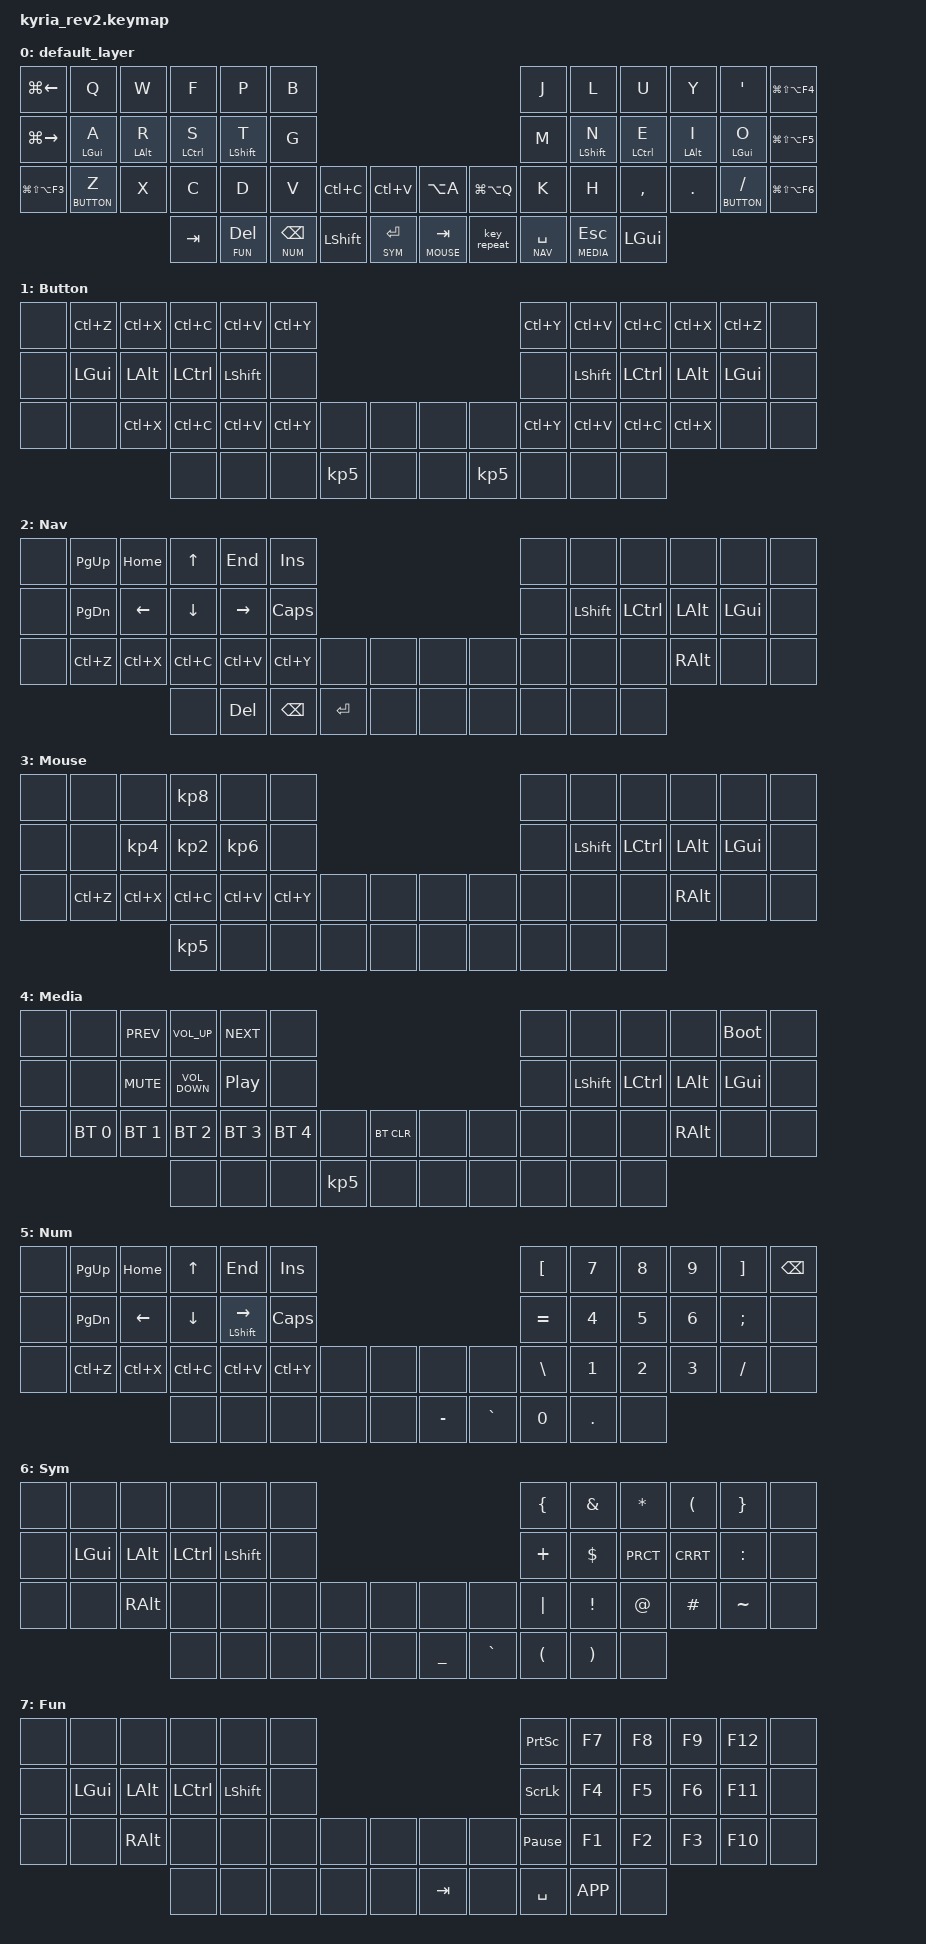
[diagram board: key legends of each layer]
/*
 * Copyright (c) 2020 The ZMK Contributors
 *
 * SPDX-License-Identifier: MIT
 */

#include <behaviors.dtsi>
#include <dt-bindings/zmk/bt.h>
#include <dt-bindings/zmk/keys.h>
// #include <dt-bindings/zmk/outputs.h>


// LAYER DEFINITIONS //
#define BASE   0
#define BUTTON 1
#define NAV    2
#define MOUSE  3
#define MEDIA  4
#define NUM    5
#define SYM    6
#define FUN    7

// CUSTOM KEY DEFINITIONS //
#define U_RDO &kp LC(Y) // WINDOWS redo
#define U_PST &kp LC(V) // WINDOWS paste
#define U_CPY &kp LC(C) // WINDOWS copy
#define U_CUT &kp LC(X) // WINDOWS cut
#define U_UND &kp LC(Z) // WINDOWS undo
#define U_SCRNSHT &kp LG(LS(S)) // WINDOWS screenshot
#define U_A_TAB &kp LA(TAB) // Alt + Tab
#define U_RUNNER &kp LA(SPACE) // Alt + Space (notes: on windows, it's slow)
#define U_M1 &kp LG(LS(LA(F1))) // To be used in conjuction with AutoHotKey
#define U_M2 &kp LG(LS(LA(F2)))
#define U_M3 &kp LG(LS(LA(F3)))
#define U_M4 &kp LG(LS(LA(F4)))
#define U_M5 &kp LG(LS(LA(F5)))
#define U_M6 &kp LG(LS(LA(F6)))
#define U_M7 &kp LG(LS(LA(F7)))
#define U_M8 &kp LG(LS(LA(F8)))

#define U_BTN1 &kp KP_N5
#define U_BTN2 &none
#define U_BTN3 &none
#define U_MS_D &kp KP_N2
#define U_MS_L &kp KP_N4
#define U_MS_R &kp KP_N6
#define U_MS_U &kp KP_N8
#define U_WH_D &none
#define U_WH_L &none
#define U_WH_R &none
#define U_WH_U &none

// HOME ROW MOD CUSTOMIZATIONS //
#define U_TAPPING_TERM 1000
#define U_TAPPING_TERM_FAST 150
#define U_TIMEOUT 50

// &left_encoder { resolution = <2>; };
// &right_encoder { resolution = <2>; };

// Shortcuts //


/ {

    macros {
/*
        my_macro: my_macro {
        compatible = "zmk,behavior-macro";
        label = "ZM_LR_BKT";
        #binding-cells = <0>;
        wait-ms = <30>;
        tap-ms = <40>;
        bindings = <&kp LBKT &kp RBKT &kp SPACE>;
        };
    
    win_right: win_right {
      label = "ZM_win_right";
      compatible = "zmk,behavior-macro";
      #binding-cells = <0>;
      wait-ms = <10>;
      bindings
        = <&macro_press &kp LGUI>
        , <&macro_tap &kp RIGHT>
        , <&macro_release &kp LGUI>
        ;
    };

    */
  };

/*
 * Layout Indices
 * 00 01 02 03 04 05               06 07 08 09 10 11
 * 12 13 14 15 16 17               18 19 20 21 22 23
 * 24 25 26 27 28 29 30 31   32 33 34 35 36 37 38 39
 *          40 41 42 43 44   45 46 47 48 49         
 */

    combos {
        compatible = "zmk,combos";
        combo_esc {
        timeout-ms = <50>;
        key-positions = <02 03>;
        bindings = <&kp ESC>;
        //layers = <BASE SYM NUM NAV>;
        };
        compatible = "zmk,combos";
        combo_screenshot {
        timeout-ms = <50>;
        key-positions = <30 31>;
        bindings = <U_SCRNSHT>;
        //layers = <BASE SYM NUM NAV>;
        };
        compatible = "zmk,combos";
        combo_leaveZoomMeeting {
        timeout-ms = <50>;
        key-positions = <32 33>;
        bindings = <&kp LA(Q)>;
        //layers = <BASE SYM NUM NAV>;
        };
        compatible = "zmk,combos";
        combo_alttab {
        timeout-ms = <50>;
        key-positions = <03 04>;
        bindings = <&kp LA(TAB)>;
        //layers = <BASE SYM NUM NAV>;
        };
        /*
        compatible = "zmk,combos";
        combo_sqrBracketsL {
        timeout-ms = <50>;
        key-positions = <07 08>;
        bindings = <&kp LBKT>;
        //layers = <BASE SYM NUM NAV>;
        };
        compatible = "zmk,combos";
        combo_sqrBracketsR {
        timeout-ms = <50>;
        key-positions = <08 09>;
        bindings = <&kp RBKT>;
        //layers = <BASE SYM NUM NAV>;
        };
        
        compatible = "zmk,combos";
        combo_LPAR {
        timeout-ms = <50>;
        key-positions = <19 20>;
        bindings = <&kp LPAR>;
        //layers = <BASE SYM NUM NAV>;
        };
        compatible = "zmk,combos";
        combo_RPAR {
        timeout-ms = <50>;
        key-positions = <20 21>;
        bindings = <&kp RPAR>;
        //layers = <BASE SYM NUM NAV>;
        };
        /*
        compatible = "zmk,combos";
        combo_leaveZoomMeeting {
        timeout-ms = <50>;
        key-positions = <07 08>;
        bindings = <&my_macro>;
        //layers = <BASE SYM NUM NAV>;
        };
        */
  };
    
    behaviors {
    hm: homerow_mods {
      compatible = "zmk,behavior-hold-tap";
      label = "HOMEROW_MODS";
      #binding-cells = <2>;
      tapping_term_ms = <U_TAPPING_TERM>;
      flavor = "tap-preferred";
      bindings = <&kp>, <&kp>;
    };
    // for faster tapping terms
    hmf: homerow_mods_fast {
      compatible = "zmk,behavior-hold-tap";
      label = "HOMEROW_MODS";
      #binding-cells = <2>;
      tapping_term_ms = <U_TAPPING_TERM_FAST>;
      flavor = "tap-preferred";
      bindings = <&kp>, <&kp>;
    };

    /*
    hm_l: homerow_mods_left {
        compatible = "zmk,behavior-hold-tap";
        label = "HOMEROW_MODS_LEFT";
        #binding-cells = <2>;
        bindings = <&kp>,  <&kp>;

        flavor = "balanced";
        tapping-term-ms = <HM_TAPPING_TERM>;
        quick-tap-ms = <175>;                // repeat on tap-into-hold
        global-quick-tap-ms = <150>;         // requires PR #1387
        hold-trigger-key-positions = <KEYS_R KEYS_T>;
        hold-trigger-on-release;             // requires PR #1423
    };

    hm_r: homerow_mods_right {
        compatible = "zmk,behavior-hold-tap";
        label = "HOMEROW_MODS_RIGHT";
        #binding-cells = <2>;
        bindings = <&kp>, <&kp>;

        flavor = "balanced";
        tapping-term-ms = <HM_TAPPING_TERM>;   
        quick_tap_ms = <175>;
        global-quick-tap-ms = <150>;         // requires PR #1387
        hold-trigger-key-positions = <KEYS_L KEYS_T>;
        hold-trigger-on-release;             // requires PR #1423
    };
    */




  };
};

/{

	keymap {
		compatible = "zmk,keymap";

		default_layer {
            
            //                                                  BASE LAYER (no longer up-to-date)
            // ╭──────────────────────────────────────────╮                             ╭──────────────────────────────────────────╮
            // │ ESC   Q         W      F       P       B │                             │ J  L       U       Y      '         BSPC │
            // │ CTRL  A         R      S       T|SHFT  G ╰───────────────╮ ╭───────────╯ M  N|SHFT  E       I      O         CNTX │
            // │ ALT   Z|BUTTON  X|ALT  C       D       V  NONE   NONE    │ │ NONE  NONE  K  H       ,       .|ALT  /|BUTTON  CTRL │
            // ╰───────────╮   SCRN  DEL|FUN  BSPC|NUM  TAB|TAB   RED|SYM │ │ TAB|MOUSE  NONE  SPC|NAV  ESC|MEDIA  WIN  ╭──────────╯
            //             ╰──────────────────────────────────────────────╯ ╰───────────────────────────────────────────╯            
            //

			bindings = <
                &kp LG(LEFT)     &kp Q             &kp W              &kp F              &kp P              &kp B                                                               &kp J               &kp L               &kp U               &kp Y               &kp SQT           U_M4
                &kp LG(RIGHT)    &hm LGUI A        &hm LALT R         &hm LCTRL S        &hmf LSHFT T       &kp G                                                               &kp M               &hmf LSHFT N        &hm LCTRL E         &hm LALT I          &hm LGUI O        U_M5
                U_M3             &lt BUTTON Z      &kp X              &kp C              &kp D              &kp V         U_CPY         U_PST        &kp LA(A)     &kp LG(LA(Q))&kp K               &kp H               &kp COMMA           &kp DOT             &lt BUTTON SLASH  U_M6
                                                                      &kp TAB            &lt FUN DEL        &lt NUM BSPC  &kp LSHIFT    &lt SYM RET  &lt MOUSE TAB &key_repeat  &lt NAV SPC         &lt MEDIA ESC       &kp LGUI
			>;
            sensor-bindings = <&inc_dec_kp C_VOL_UP C_VOL_DN>;
			//sensor-bindings = <&inc_dec_kp DOWN UP &inc_dec_kp PG_DN PG_UP>;
		};

        BUTTON_layer {                                       
              label = "Button"; //MIRYOKU_ALTERNATIVES_BUTTON                                      
            bindings = <                                       
                &none  U_UND             U_CUT              U_CPY              U_PST              U_RDO                                                            U_RDO               U_PST               U_CPY               U_CUT               U_UND             &none
                &none  &kp LGUI          &kp LALT           &kp LCTRL          &kp LSHFT          &none                                                            &none               &kp LSHFT           &kp LCTRL           &kp LALT            &kp LGUI          &none
                &none  &none             U_CUT              U_CPY              U_PST              U_RDO         &none          &none     &none      &none          U_RDO               U_PST               U_CPY               U_CUT               &none             &none
                                                            &none              U_BTN2             U_BTN3        U_BTN1         &none     &none      U_BTN1         U_BTN3              U_BTN2              &none
            >;        
        };  
        NAV_layer {  
            label = "Nav";  //MIRYOKU_ALTERNATIVES_NAV_INVERTEDT_FLIP
            bindings = <  
                &none  &kp PG_UP         &kp HOME           &kp UP             &kp END            &kp INS                                                          &none               &none               &none               &none               &none            &none
                &none  &kp PG_DN         &kp LEFT           &kp DOWN           &kp RIGHT          &kp CAPS                                                         &none               &kp LSHFT           &kp LCTRL           &kp LALT            &kp LGUI         &none
                &none  U_UND             U_CUT              U_CPY              U_PST              U_RDO         &none          &none     &none      &none          &none               &none               &none               &kp RALT            &none            &none
                                                            &none              &kp DEL            &kp BSPC      &kp RET        &none     &none      &none          &none               &none               &none   
            >;      
        };      
        MOUSE_layer {      
            label = "Mouse"; //MIRYOKU_ALTERNATIVES_MOUSE_INVERTEDT_FLIP     
            bindings = <     
                &none  U_WH_U            U_WH_L             U_MS_U             U_WH_R             &none                                                            &none               &none               &none               &none               &none            &none   
                &none  U_WH_D            U_MS_L             U_MS_D             U_MS_R             &none                                                            &none               &kp LSHFT           &kp LCTRL           &kp LALT            &kp LGUI         &none   
                &none  U_UND             U_CUT              U_CPY              U_PST              U_RDO         &none          &none     &none      &none          &none               &none               &none               &kp RALT            &none            &none   
                                                            U_BTN1             U_BTN2             U_BTN3        &none          &none     &none      &none          &none               &none               &none
            >;      
        };      
        MEDIA_layer {      
            label = "Media"; //MIRYOKU_ALTERNATIVES_MEDIA_INVERTEDT_FLIP
            bindings = <       
                &none  &none             &kp C_PREV         &kp C_VOL_UP       &kp C_NEXT         &none                                                            &none               &none               &none               &none               &bootloader      &none   
                &none  &none             &kp C_MUTE         &kp C_VOLUME_DOWN  &kp C_PLAY_PAUSE   &none                                                            &none               &kp LSHFT           &kp LCTRL           &kp LALT            &kp LGUI         &none   
                &none  &bt BT_SEL 0      &bt BT_SEL 1       &bt BT_SEL 2       &bt BT_SEL 3       &bt BT_SEL 4  &none          &bt BT_CLR&none      &none          &none               &none               &none               &kp RALT            &none            &none   
                                                            &none              U_BTN2             U_BTN3        U_BTN1         &none     &none      &none          &none               &none               &none 
            >;      
        };      
        NUM_layer {      
            label = "Num";  //MIRYOKU_ALTERNATIVES_NUM_FLIP    
            bindings = <      
                &none  &kp PG_UP         &kp HOME           &kp UP             &kp END            &kp INS                                                          &kp LBKT            &kp NUM_7           &kp NUM_8           &kp NUM_9           &kp RBKT         &kp BSPC   
                &none  &kp PG_DN         &kp LEFT           &kp DOWN           &hmf LSHIFT RIGHT  &kp CAPS                                                         &kp EQL             &kp NUM_4           &kp NUM_5           &kp NUM_6           &kp SEMI         &none   
                &none  U_UND             U_CUT              U_CPY              U_PST              U_RDO          &none         &none     &none      &none          &kp BSLH            &kp NUM_1           &kp NUM_2           &kp NUM_3           &kp SLASH        &none   
                                                            &none              &none              &none          &none         &none     &kp MINUS  &kp GRAVE      &kp NUM_0           &kp DOT             &none    
            >;     
        };     
        SYM_layer {     
            label = "Sym";  //MIRYOKU_ALTERNATIVES_SYM_FLIP   
            bindings = <      
                &none  &none             &none              &none              &none              &none                                                            &kp LBRC            &kp AMPS            &kp ASTRK           &kp LPAR            &kp RBRC         &none   
                &none  &kp LGUI          &kp LALT           &kp LCTRL          &kp LSHFT          &none                                                            &kp PLUS            &kp DLLR            &kp PRCT            &kp CRRT            &kp COLON        &none   
                &none  &none             &kp RALT           &none              &none              &none          &none         &none     &none      &none          &kp PIPE            &kp EXCL            &kp AT              &kp HASH            &kp TILDE        &none   
                                                            &none              &none              &none          &none         &none     &kp UNDER  &kp GRAVE      &kp LPAR            &kp RPAR            &none   
            >;     
        };     
        FUN_layer {     
            label = "Fun"; //MIRYOKU_ALTERNATIVES_FUN_FLIP    
            bindings = <      
                &none  &none             &none              &none              &none              &none                                                            &kp PSCRN           &kp F7              &kp F8              &kp F9              &kp F12          &none   
                &none  &kp LGUI          &kp LALT           &kp LCTRL          &kp LSHFT          &none                                                            &kp SLCK            &kp F4              &kp F5              &kp F6              &kp F11          &none   
                &none  &none             &kp RALT           &none              &none              &none          &none         &none     &none      &none          &kp PAUSE_BREAK     &kp F1              &kp F2              &kp F3              &kp F10          &none   
                                                            &none              &none              &none          &none         &none     &kp TAB    &none          &kp SPC             &kp K_APP           &none
            >;
        };
    };

};

